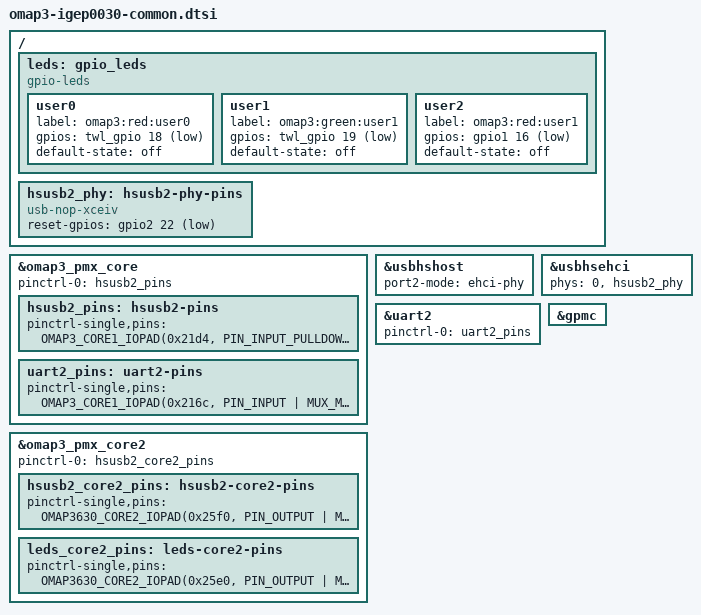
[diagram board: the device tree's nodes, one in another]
#include "omap3-igep.dtsi"
/ {
	leds: gpio_leds {
		compatible = "gpio-leds";
		user0 {
			 label = "omap3:red:user0";
			 gpios = <&twl_gpio 18 GPIO_ACTIVE_LOW>;	 
			 default-state = "off";
		};
		user1 {
			 label = "omap3:green:user1";
			 gpios = <&twl_gpio 19 GPIO_ACTIVE_LOW>;	 
			 default-state = "off";
		};
		user2 {
			 label = "omap3:red:user1";
			 gpios = <&gpio1 16 GPIO_ACTIVE_LOW>;		 
			 default-state = "off";
		};
	};
	hsusb2_phy: hsusb2-phy-pins {
		compatible = "usb-nop-xceiv";
		reset-gpios = <&gpio2 22 GPIO_ACTIVE_LOW>;		 
		#phy-cells = <0>;
	};
};
&omap3_pmx_core {
	pinctrl-names = "default";
	pinctrl-0 = <&hsusb2_pins>;
	hsusb2_pins: hsusb2-pins {
		pinctrl-single,pins = <
			OMAP3_CORE1_IOPAD(0x21d4, PIN_INPUT_PULLDOWN | MUX_MODE3)	 
			OMAP3_CORE1_IOPAD(0x21d6, PIN_INPUT_PULLDOWN | MUX_MODE3)	 
			OMAP3_CORE1_IOPAD(0x21d8, PIN_INPUT_PULLDOWN | MUX_MODE3)	 
			OMAP3_CORE1_IOPAD(0x21da, PIN_INPUT_PULLDOWN | MUX_MODE3)	 
			OMAP3_CORE1_IOPAD(0x21dc, PIN_INPUT_PULLDOWN | MUX_MODE3)	 
			OMAP3_CORE1_IOPAD(0x21de, PIN_INPUT_PULLDOWN | MUX_MODE3)	 
		>;
	};
	uart2_pins: uart2-pins {
		pinctrl-single,pins = <
			OMAP3_CORE1_IOPAD(0x216c, PIN_INPUT | MUX_MODE1)	 
			OMAP3_CORE1_IOPAD(0x216e, PIN_OUTPUT | MUX_MODE1)	 
			OMAP3_CORE1_IOPAD(0x2170, PIN_OUTPUT | MUX_MODE1)	 
			OMAP3_CORE1_IOPAD(0x2172, PIN_INPUT | MUX_MODE1)	 
		>;
	};
};
&omap3_pmx_core2 {
	pinctrl-names = "default";
	pinctrl-0 = <&hsusb2_core2_pins>;
	hsusb2_core2_pins: hsusb2-core2-pins {
		pinctrl-single,pins = <
			OMAP3630_CORE2_IOPAD(0x25f0, PIN_OUTPUT | MUX_MODE3)		       
			OMAP3630_CORE2_IOPAD(0x25f2, PIN_OUTPUT | MUX_MODE3)		       
			OMAP3630_CORE2_IOPAD(0x25f4, PIN_INPUT_PULLDOWN | MUX_MODE3)	 
			OMAP3630_CORE2_IOPAD(0x25f6, PIN_INPUT_PULLDOWN | MUX_MODE3)	 
			OMAP3630_CORE2_IOPAD(0x25f8, PIN_INPUT_PULLDOWN | MUX_MODE3)	 
			OMAP3630_CORE2_IOPAD(0x25fa, PIN_INPUT_PULLDOWN | MUX_MODE3)	 
		>;
	};
	leds_core2_pins: leds-core2-pins {
		pinctrl-single,pins = <
			OMAP3630_CORE2_IOPAD(0x25e0, PIN_OUTPUT | MUX_MODE4)	 
		>;
	};
};
&usbhshost {
	port2-mode = "ehci-phy";
};
&usbhsehci {
	phys = <0 &hsusb2_phy>;
};
&uart2 {
	pinctrl-names = "default";
	pinctrl-0 = <&uart2_pins>;
};
&gpmc {
	ranges = <0 0 0x30000000 0x01000000>;    
};
